AUTOSAR XML (schema 4-2-2)
package /ComponentTypes
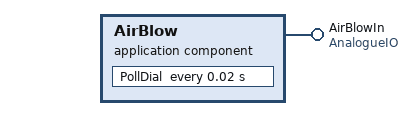
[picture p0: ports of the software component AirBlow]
  application sw component type AirBlow
    provide port AirBlowIn: nonqueued-sender-com-spec{data-element=speed, init-value=0}, provided-interface=AnalogueIO
    behavior AirBlow_InternalBehavior: data-type-mapping=speedMapSet
      timing event TMT_PollDial: start-on-event=PollDial, period=0.02
      runnable PollDial
        data-send-points:
          access SEND_AirBlowIn_speed: accessed-variable=AirBlowIn.speed
  swc implementation AirBlow_Implementation: behavior=AirBlow_InternalBehavior
